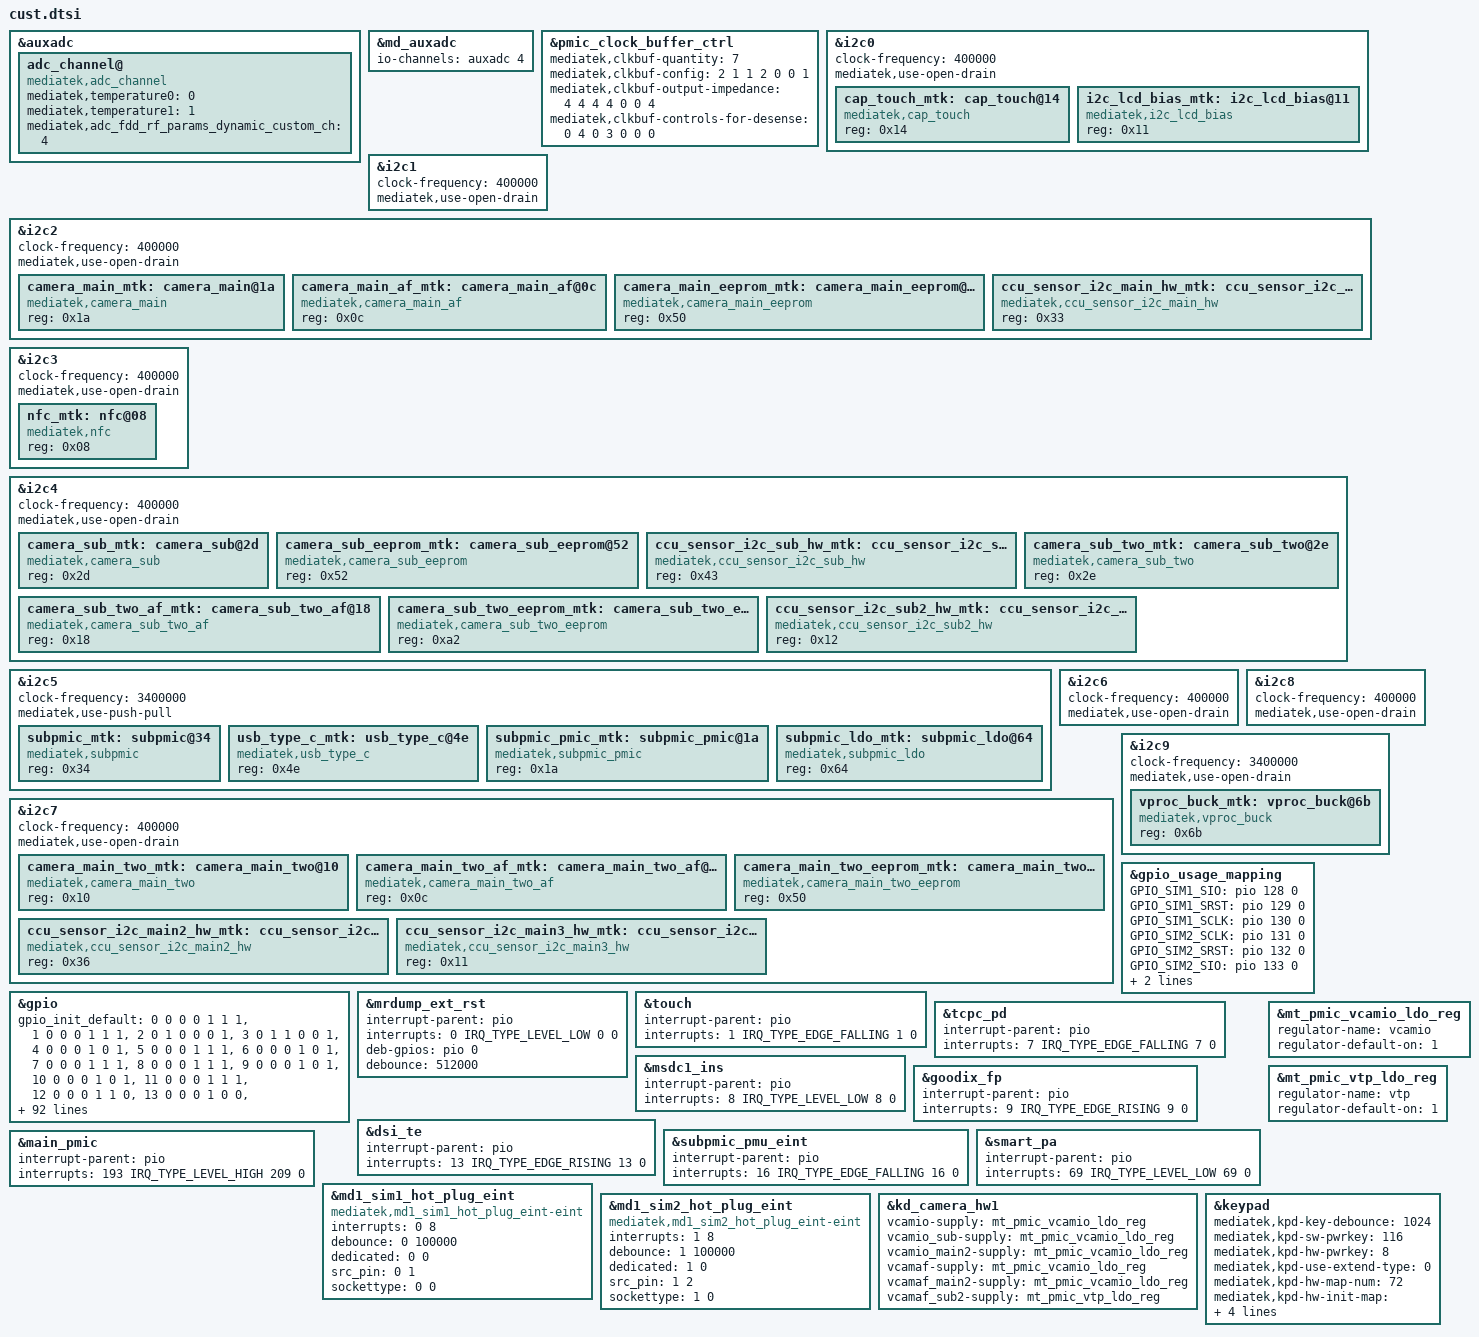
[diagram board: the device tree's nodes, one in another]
/*
 * Generated by MTK SP DrvGen Version: 3.5.160809 for MT6785.
 * 2021-08-29 11:08:43
 * Do Not Modify The File.
 * Copyright Mediatek Inc. (c) 2016.
*/

/*************************
 * ADC DTSI File
*************************/

&auxadc {
	adc_channel@ {
		compatible = "mediatek,adc_channel";
		mediatek,temperature0 = <0>;
		mediatek,temperature1 = <1>;
		mediatek,adc_fdd_rf_params_dynamic_custom_ch = <4>;
		status = "okay";
	};
};
&md_auxadc {
	io-channels = <&auxadc 4>;
};


/*************************
 * CLK_BUF DTSI File
*************************/

&pmic_clock_buffer_ctrl {
	mediatek,clkbuf-quantity = <7>;
	mediatek,clkbuf-config = <2 1 1 2 0 0 1>;
	mediatek,clkbuf-output-impedance = <4 4 4 4 0 0 4>;
	mediatek,clkbuf-controls-for-desense = <0 4 0 3 0 0 0>;
	status = "okay";
};


/*************************
 * I2C DTSI File
*************************/

&i2c0 {
	#address-cells = <1>;
	#size-cells = <0>;
	clock-frequency = <400000>;
	mediatek,use-open-drain;
	cap_touch_mtk:cap_touch@14 {
		compatible = "mediatek,cap_touch";
		reg = <0x14>;
		status = "okay";
	};

	i2c_lcd_bias_mtk:i2c_lcd_bias@11 {
		compatible = "mediatek,i2c_lcd_bias";
		reg = <0x11>;
		status = "okay";
	};

};

&i2c1 {
	#address-cells = <1>;
	#size-cells = <0>;
	clock-frequency = <400000>;
	mediatek,use-open-drain;
};

&i2c2 {
	#address-cells = <1>;
	#size-cells = <0>;
	clock-frequency = <400000>;
	mediatek,use-open-drain;
	camera_main_mtk:camera_main@1a {
		compatible = "mediatek,camera_main";
		reg = <0x1a>;
		status = "okay";
	};

	camera_main_af_mtk:camera_main_af@0c {
		compatible = "mediatek,camera_main_af";
		reg = <0x0c>;
		status = "okay";
	};

	camera_main_eeprom_mtk:camera_main_eeprom@50 {
		compatible = "mediatek,camera_main_eeprom";
		reg = <0x50>;
		status = "okay";
	};

	ccu_sensor_i2c_main_hw_mtk:ccu_sensor_i2c_main_hw@33 {
		compatible = "mediatek,ccu_sensor_i2c_main_hw";
		reg = <0x33>;
		status = "okay";
	};

};

&i2c3 {
	#address-cells = <1>;
	#size-cells = <0>;
	clock-frequency = <400000>;
	mediatek,use-open-drain;
	nfc_mtk:nfc@08 {
		compatible = "mediatek,nfc";
		reg = <0x08>;
		status = "okay";
	};

};

&i2c4 {
	#address-cells = <1>;
	#size-cells = <0>;
	clock-frequency = <400000>;
	mediatek,use-open-drain;
	camera_sub_mtk:camera_sub@2d {
		compatible = "mediatek,camera_sub";
		reg = <0x2d>;
		status = "okay";
	};

	camera_sub_eeprom_mtk:camera_sub_eeprom@52 {
		compatible = "mediatek,camera_sub_eeprom";
		reg = <0x52>;
		status = "okay";
	};

	ccu_sensor_i2c_sub_hw_mtk:ccu_sensor_i2c_sub_hw@43 {
		compatible = "mediatek,ccu_sensor_i2c_sub_hw";
		reg = <0x43>;
		status = "okay";
	};

	camera_sub_two_mtk:camera_sub_two@2e {
		compatible = "mediatek,camera_sub_two";
		reg = <0x2e>;
		status = "okay";
	};

	camera_sub_two_af_mtk:camera_sub_two_af@18 {
		compatible = "mediatek,camera_sub_two_af";
		reg = <0x18>;
		status = "okay";
	};

	camera_sub_two_eeprom_mtk:camera_sub_two_eeprom@a2 {
		compatible = "mediatek,camera_sub_two_eeprom";
		reg = <0xa2>;
		status = "okay";
	};

	ccu_sensor_i2c_sub2_hw_mtk:ccu_sensor_i2c_sub2_hw@12 {
		compatible = "mediatek,ccu_sensor_i2c_sub2_hw";
		reg = <0x12>;
		status = "okay";
	};

};

&i2c5 {
	#address-cells = <1>;
	#size-cells = <0>;
	clock-frequency = <3400000>;
	mediatek,use-push-pull;
	subpmic_mtk:subpmic@34 {
		compatible = "mediatek,subpmic";
		reg = <0x34>;
		status = "okay";
	};

	usb_type_c_mtk:usb_type_c@4e {
		compatible = "mediatek,usb_type_c";
		reg = <0x4e>;
		status = "okay";
	};

	subpmic_pmic_mtk:subpmic_pmic@1a {
		compatible = "mediatek,subpmic_pmic";
		reg = <0x1a>;
		status = "okay";
	};

	subpmic_ldo_mtk:subpmic_ldo@64 {
		compatible = "mediatek,subpmic_ldo";
		reg = <0x64>;
		status = "okay";
	};

};

&i2c6 {
	#address-cells = <1>;
	#size-cells = <0>;
	clock-frequency = <400000>;
	mediatek,use-open-drain;
};

&i2c7 {
	#address-cells = <1>;
	#size-cells = <0>;
	clock-frequency = <400000>;
	mediatek,use-open-drain;
	camera_main_two_mtk:camera_main_two@10 {
		compatible = "mediatek,camera_main_two";
		reg = <0x10>;
		status = "okay";
	};

	camera_main_two_af_mtk:camera_main_two_af@0c {
		compatible = "mediatek,camera_main_two_af";
		reg = <0x0c>;
		status = "okay";
	};

	camera_main_two_eeprom_mtk:camera_main_two_eeprom@50 {
		compatible = "mediatek,camera_main_two_eeprom";
		reg = <0x50>;
		status = "okay";
	};

	ccu_sensor_i2c_main2_hw_mtk:ccu_sensor_i2c_main2_hw@36 {
		compatible = "mediatek,ccu_sensor_i2c_main2_hw";
		reg = <0x36>;
		status = "okay";
	};

	ccu_sensor_i2c_main3_hw_mtk:ccu_sensor_i2c_main3_hw@11 {
		compatible = "mediatek,ccu_sensor_i2c_main3_hw";
		reg = <0x11>;
		status = "okay";
	};

};

&i2c8 {
	#address-cells = <1>;
	#size-cells = <0>;
	clock-frequency = <400000>;
	mediatek,use-open-drain;
};

&i2c9 {
	#address-cells = <1>;
	#size-cells = <0>;
	clock-frequency = <3400000>;
	mediatek,use-open-drain;
	vproc_buck_mtk:vproc_buck@6b {
		compatible = "mediatek,vproc_buck";
		reg = <0x6b>;
		status = "okay";
	};

};



/*************************
 * GPIO DTSI File
*************************/

&gpio_usage_mapping {
	GPIO_SIM1_SIO = <&pio 128 0>;
	GPIO_SIM1_SRST = <&pio 129 0>;
	GPIO_SIM1_SCLK = <&pio 130 0>;
	GPIO_SIM2_SCLK = <&pio 131 0>;
	GPIO_SIM2_SRST = <&pio 132 0>;
	GPIO_SIM2_SIO = <&pio 133 0>;
	GPIO_SIM1_HOT_PLUG = <&pio 140 0>;
	GPIO_SIM2_HOT_PLUG = <&pio 141 0>;
};

&gpio{
	gpio_init_default = <0 0 0 0 1 1 1>,
		<1 0 0 0 1 1 1>,
		<2 0 1 0 0 0 1>,
		<3 0 1 1 0 0 1>,
		<4 0 0 0 1 0 1>,
		<5 0 0 0 1 1 1>,
		<6 0 0 0 1 0 1>,
		<7 0 0 0 1 1 1>,
		<8 0 0 0 1 1 1>,
		<9 0 0 0 1 0 1>,
		<10 0 0 0 1 0 1>,
		<11 0 0 0 1 1 1>,
		<12 0 0 0 1 1 0>,
		<13 0 0 0 1 0 0>,
		<14 0 1 0 0 0 0>,
		<15 0 1 0 0 0 0>,
		<16 0 0 0 1 1 1>,
		<17 1 0 0 1 0 0>,
		<18 1 1 0 0 0 0>,
		<19 1 1 0 0 0 0>,
		<20 1 1 0 0 0 0>,
		<21 0 1 0 0 0 0>,
		<22 0 1 1 0 0 0>,
		<23 0 1 0 0 0 0>,
		<24 0 1 0 0 0 0>,
		<25 1 0 0 1 0 0>,
		<26 0 1 0 0 0 0>,
		<28 1 0 0 1 1 1>,
		<29 1 0 0 1 1 1>,
		<30 0 1 0 0 0 0>,
		<31 0 1 0 0 0 0>,
		<32 0 1 0 0 0 0>,
		<33 0 0 0 1 0 0>,
		<34 0 1 0 0 0 0>,
		<35 5 1 0 0 0 0>,
		<36 5 1 0 0 0 0>,
		<37 5 0 0 1 0 0>,
		<38 5 1 0 0 0 0>,
		<39 6 0 0 1 0 0>,
		<40 6 0 0 1 0 0>,
		<41 6 0 0 1 0 0>,
		<42 1 1 0 0 0 0>,
		<43 0 0 0 1 0 0>,
		<44 0 1 0 0 0 0>,
		<45 1 0 0 1 1 1>,
		<46 1 0 0 1 1 1>,
		<47 1 0 0 1 1 0>,
		<48 1 1 1 0 0 0>,
		<49 1 1 0 0 0 0>,
		<50 1 1 0 0 0 0>,
		<51 1 0 0 1 1 1>,
		<52 1 0 0 1 1 1>,
		<53 1 0 0 1 1 0>,
		<54 1 1 1 0 0 0>,
		<55 1 0 0 1 1 1>,
		<56 1 0 0 1 1 1>,
		<57 0 0 0 1 0 0>,
		<58 0 0 0 1 0 0>,
		<59 1 0 0 1 1 0>,
		<60 1 0 0 1 1 0>,
		<61 2 0 0 1 1 1>,
		<62 2 0 0 1 1 1>,
		<63 2 0 0 1 0 0>,
		<64 2 1 0 0 0 0>,
		<65 2 1 0 0 0 0>,
		<66 2 1 0 0 0 0>,
		<67 1 1 0 0 0 1>,
		<68 1 1 0 0 0 1>,
		<69 0 0 0 1 1 1>,
		<70 1 0 0 1 0 0>,
		<71 1 1 0 0 0 1>,
		<72 1 0 0 1 0 0>,
		<73 3 0 0 1 0 0>,
		<74 3 0 0 1 0 0>,
		<75 1 0 0 1 0 0>,
		<76 1 0 0 1 0 0>,
		<77 1 0 0 1 0 0>,
		<78 1 0 0 1 0 0>,
		<79 1 0 0 1 0 0>,
		<80 1 0 0 1 0 0>,
		<81 1 0 0 1 0 0>,
		<82 1 0 0 1 0 0>,
		<83 1 0 0 1 0 0>,
		<84 1 0 0 1 0 0>,
		<85 1 0 0 1 0 0>,
		<86 1 0 0 1 0 0>,
		<87 1 0 0 1 0 0>,
		<88 1 0 0 1 0 0>,
		<89 1 0 0 1 0 0>,
		<90 1 0 0 1 0 0>,
		<91 1 0 0 1 0 0>,
		<92 1 0 0 1 0 0>,
		<93 0 1 0 0 0 0>,
		<94 1 0 0 1 0 0>,
		<95 1 0 0 1 0 0>,
		<96 1 0 0 1 0 0>,
		<97 1 0 0 1 0 0>,
		<98 1 0 0 1 0 0>,
		<99 1 0 0 1 0 0>,
		<100 1 0 0 1 0 0>,
		<101 1 0 0 1 0 0>,
		<102 1 0 0 1 0 0>,
		<103 1 0 0 1 0 0>,
		<104 1 0 0 1 0 0>,
		<105 1 0 0 1 0 0>,
		<106 1 0 0 1 0 0>,
		<107 1 0 0 1 0 0>,
		<108 1 0 0 1 0 0>,
		<109 1 0 0 1 0 0>,
		<110 1 0 0 1 1 1>,
		<111 1 0 0 1 1 1>,
		<112 1 0 0 1 1 1>,
		<113 1 0 0 1 1 1>,
		<114 0 1 0 0 0 0>,
		<115 0 1 0 0 0 0>,
		<116 1 1 0 0 0 0>,
		<117 1 1 0 0 0 0>,
		<118 0 1 0 0 0 0>,
		<119 0 1 0 0 0 0>,
		<120 1 1 0 0 0 0>,
		<121 1 1 0 0 0 0>,
		<122 0 1 0 0 0 0>,
		<123 0 1 0 0 0 0>,
		<124 0 1 0 0 0 0>,
		<125 0 1 0 0 0 0>,
		<126 0 1 0 0 0 0>,
		<127 0 1 0 0 0 0>,
		<128 1 0 0 1 1 1>,
		<129 1 1 0 0 0 1>,
		<130 1 1 0 0 0 1>,
		<131 1 1 0 0 0 1>,
		<132 1 1 0 0 0 1>,
		<133 1 0 0 1 1 1>,
		<134 1 1 0 0 0 1>,
		<135 1 0 0 1 1 1>,
		<136 1 0 0 1 1 1>,
		<137 1 0 0 1 1 1>,
		<138 1 0 0 1 1 1>,
		<139 1 0 0 1 1 1>,
		<140 1 0 0 1 1 1>,
		<141 1 0 0 1 1 1>,
		<142 1 1 0 0 0 0>,
		<143 1 1 0 0 0 1>,
		<144 1 1 0 0 0 1>,
		<145 1 1 0 0 0 1>,
		<146 1 0 0 1 0 1>,
		<147 0 0 0 1 0 0>,
		<148 0 0 0 1 0 0>,
		<149 0 0 0 1 0 0>,
		<150 4 1 0 0 0 0>,
		<151 1 0 0 1 1 1>,
		<152 1 0 0 1 1 1>,
		<153 0 0 0 1 0 0>,
		<154 1 0 0 0 0 1>,
		<155 1 0 0 0 0 1>,
		<156 0 1 0 0 0 0>,
		<157 0 1 0 0 0 0>,
		<158 0 1 0 0 0 0>,
		<159 0 1 0 0 0 0>,
		<160 0 1 0 0 0 0>,
		<161 0 1 0 0 0 0>,
		<162 0 1 0 0 0 0>,
		<163 0 1 0 0 0 0>,
		<164 0 1 0 0 0 0>,
		<165 0 0 0 1 0 0>,
		<166 0 0 0 1 0 0>,
		<179 1 0 0 1 0 0>,
		<180 1 0 0 1 0 0>,
		<181 1 1 0 0 0 0>,
		<182 1 1 0 0 0 0>,
		<183 1 1 0 0 0 0>,
		<184 1 0 0 1 0 0>,
		<185 1 1 0 0 0 0>,
		<186 1 0 0 1 0 0>,
		<187 1 1 0 0 0 0>,
		<188 1 0 0 1 0 1>,
		<189 1 1 0 0 0 1>,
		<190 1 1 0 0 0 1>,
		<191 1 1 0 0 0 1>,
		<192 1 1 0 0 0 1>,
		<193 1 0 0 1 0 1>,
		<194 1 0 0 1 0 1>,
		<195 0 1 0 0 0 0>,
		<196 1 1 0 0 0 0>,
		<197 0 1 0 0 0 0>,
		<198 1 0 0 1 1 1>,
		<199 1 0 0 1 1 1>,
		<200 1 0 0 1 1 0>,
		<201 1 1 0 0 0 0>,
		<202 0 1 0 0 0 0>,
		<203 0 0 0 1 0 0>,
		<204 0 0 0 1 0 0>,
		<205 0 0 0 1 0 0>,
		<206 0 0 0 1 0 0>,
		<207 0 0 0 1 0 0>,
		<208 0 0 0 1 0 0>,
		<209 0 0 0 1 0 0>,
		<210 0 0 0 1 0 0>;
};


/*************************
 * EINT DTSI File
*************************/

#include <dt-bindings/interrupt-controller/irq.h>
#include <dt-bindings/interrupt-controller/arm-gic.h>

&mrdump_ext_rst {
	interrupt-parent = <&pio>;
	interrupts = <0 IRQ_TYPE_LEVEL_LOW 0 0>;
	deb-gpios = <&pio 0 0>;
	debounce = <512000>;
	status = "okay";
};

&touch {
	interrupt-parent = <&pio>;
	interrupts = <1 IRQ_TYPE_EDGE_FALLING 1 0>;
	status = "okay";
};

&tcpc_pd {
	interrupt-parent = <&pio>;
	interrupts = <7 IRQ_TYPE_EDGE_FALLING 7 0>;
	status = "okay";
};

&msdc1_ins {
	interrupt-parent = <&pio>;
	interrupts = <8 IRQ_TYPE_LEVEL_LOW 8 0>;
	status = "okay";
};

&goodix_fp {
	interrupt-parent = <&pio>;
	interrupts = <9 IRQ_TYPE_EDGE_RISING 9 0>;
	status = "okay";
};

&dsi_te {
	interrupt-parent = <&pio>;
	interrupts = <13 IRQ_TYPE_EDGE_RISING 13 0>;
	status = "okay";
};

&subpmic_pmu_eint {
	interrupt-parent = <&pio>;
	interrupts = <16 IRQ_TYPE_EDGE_FALLING 16 0>;
	status = "okay";
};

&smart_pa {
	interrupt-parent = <&pio>;
	interrupts = <69 IRQ_TYPE_LEVEL_LOW 69 0>;
	status = "okay";
};

&main_pmic {
	interrupt-parent = <&pio>;
	interrupts = <193 IRQ_TYPE_LEVEL_HIGH 209 0>;
	status = "okay";
};



/*************************
 * MD1_EINT DTSI File
*************************/

&md1_sim1_hot_plug_eint {
	compatible = "mediatek,md1_sim1_hot_plug_eint-eint";
	interrupts = <0 8>;
	debounce = <0 100000>;
	dedicated = <0 0>;
	src_pin = <0 1>;
	sockettype = <0 0>;
	status = "okay";
};

&md1_sim2_hot_plug_eint {
	compatible = "mediatek,md1_sim2_hot_plug_eint-eint";
	interrupts = <1 8>;
	debounce = <1 100000>;
	dedicated = <1 0>;
	src_pin = <1 2>;
	sockettype = <1 0>;
	status = "okay";
};



/*************************
 * PMIC DTSI File
*************************/

&mt_pmic_vcamio_ldo_reg {
	regulator-name = "vcamio";
	regulator-default-on = <1>; /* 0:skip, 1: off, 2:on */
	status = "okay";
};
&mt_pmic_vtp_ldo_reg {
	regulator-name = "vtp";
	regulator-default-on = <1>; /* 0:skip, 1: off, 2:on */
	status = "okay";
};

&kd_camera_hw1 {
	vcamio-supply = <&mt_pmic_vcamio_ldo_reg>;
	vcamio_sub-supply = <&mt_pmic_vcamio_ldo_reg>;
	vcamio_main2-supply = <&mt_pmic_vcamio_ldo_reg>;
	vcamaf-supply = <&mt_pmic_vcamio_ldo_reg>;
	vcamaf_main2-supply = <&mt_pmic_vcamio_ldo_reg>;
	vcamaf_sub2-supply = <&mt_pmic_vtp_ldo_reg>;
	status = "okay";
};

&touch {
	status = "okay";
};


/*************************
 * POWER DTSI File
*************************/



/*************************
 * KPD DTSI File
*************************/

&keypad {
	mediatek,kpd-key-debounce = <1024>;
	mediatek,kpd-sw-pwrkey = <116>;
	mediatek,kpd-hw-pwrkey = <8>;
	mediatek,kpd-use-extend-type = <0>;
	/*HW Keycode [0~71] -> Linux Keycode*/
	mediatek,kpd-hw-map-num = <72>;
	mediatek,kpd-hw-init-map = <115 114 0 0 0 0 0 0 0 0 0 0 0 0 0 0 0 0 0 0 0 0 0 0 0 0 0 0 0 0 0 0 0 0 0 0 0 0 0 0 0 0 0 0 0 0 0 0 0 0 0 0 0 0 0 0 0 0 0 0 0 0 0 0 0 0 0 0 0 0 0 0 >;
	mediatek,kpd-pwrkey-eint-gpio = <0>;
	mediatek,kpd-pwkey-gpio-din  = <0>;
	mediatek,kpd-hw-dl-key0 = <0>;
	status = "okay";
};
